# MDR1206AFI register map
Vendor: Milandr; File version: 2.0
CPU: BM-310S0, little endian
Registers are 32-bit, read-write, reset 0x0 unless marked. A register's access mark holds for its fields unless they carry their own. Offsets are from the block's base; [hi:lo] are bit positions; {n}, {i} and the like mark numbered series; 'fields as' and 'values as' point back to an identical list.

## DMA — DMA Controller
Base 0x50028000
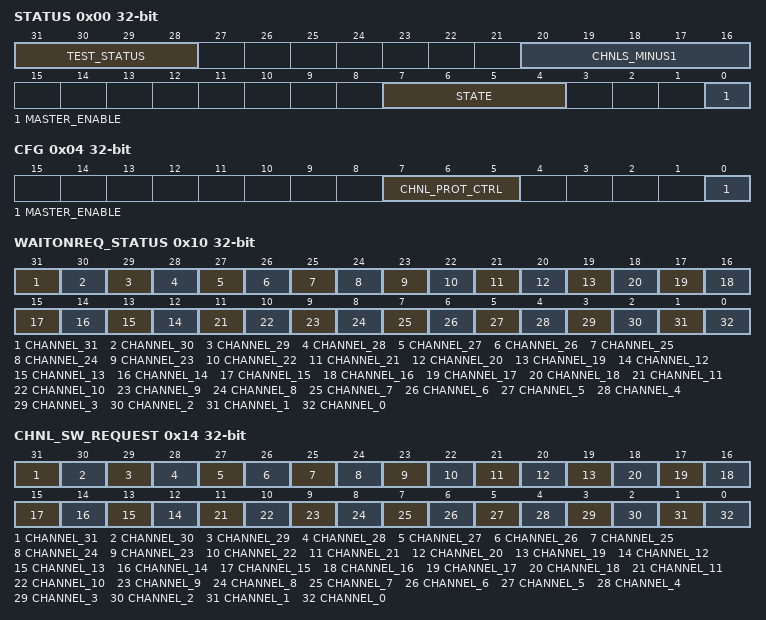
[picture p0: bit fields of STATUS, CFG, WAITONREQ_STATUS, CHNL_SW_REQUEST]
0x00 STATUS ro
  [31:28] TEST_STATUS — Defines if there is an in-built testing system
    0=NO_TESTING_SYSTEM; 1=TESTING_SYSTEM
  [20:16] CHNLS_MINUS1 — The number of available DMA channels minus one
  [7:4] STATE — A current state of the DMA Controller
    0=idle; 1=reading channel control data; 2=reading source data end pointer; 3=reading destination data end pointer; 4=reading source data; 5=writing destination data; 6=waiting for DMA request to clear; 7=writing channel controller data; 8=stalled; 9=done; 10=peripheral scatter-gather transition; 11=undefined
  [0] MASTER_ENABLE — Enables the status of the controller
    0=The controller is disabled; 1=The controller is enabled
0x04 CFG — DMA Configuration Register
  [7:5] CHNL_PROT_CTRL wo — Sets the AHB-Lite protection by controlling the HPROT[3:1] signal levels
  [0] MASTER_ENABLE wo — Enables the DMA controller
    0=Disables DMA; 1=Enables DMA
0x08 CTRL_BASE_PTR — Channel control data base pointer
0x0C ALT_CTRL_BASE_PTR ro — Channel alternate control data base pointer
0x10 WAITONREQ_STATUS ro — Channel wait on request status
  [31] CHANNEL_31
  [30] CHANNEL_30 — CHANNEL_30: SAR ADC
  [29] CHANNEL_29 — CHANNEL_26
  [28] CHANNEL_28
  [27] CHANNEL_27
  [26] CHANNEL_26
  [25] CHANNEL_25 — CHANNEL_25: UART4 RX
  [24] CHANNEL_24 — CHANNEL_24: UART4 TX
  [23] CHANNEL_23 — CHANNEL_23: TIMER4
  [22] CHANNEL_22 — CHANNEL_22: SSP3 RX
  [21] CHANNEL_21 — CHANNEL_21: SSP3 TX
  [20] CHANNEL_20 — CHANNEL_20: SSP2 RX
  [19] CHANNEL_19 — CHANNEL_19: SSP2 TX
  [n] CHANNEL_{n} (n=12..18) — CHANNEL_{n}: ADCUI{n-11}
  [11] CHANNEL_11 — CHANNEL_11: TIMER2
  [10] CHANNEL_10 — CHANNEL_10: TIMER1
  [9] CHANNEL_9 — CHANNEL_9: TIMER3
  [8] CHANNEL_8 — CHANNEL_8: UART3 RX
  [7] CHANNEL_7 — CHANNEL_7: UART3 TX
  [6] CHANNEL_6 — CHANNEL_6: CRC
  [5] CHANNEL_5 — CHANNEL_5: SSP1 RX
  [4] CHANNEL_4 — CHANNEL_4: SSP1 TX
  [3] CHANNEL_3 — CHANNEL_3: UART2 RX
  [2] CHANNEL_2 — CHANNEL_2: UART2 TX
  [1] CHANNEL_1 — CHANNEL_1: UART1 RX
  [0] CHANNEL_0 — CHANNEL_0: UART1 TX
0x14 CHNL_SW_REQUEST wo — Channel software request. Set the appropriate bit to generate a software DMA request on the corresponding DMA channel
  fields as WAITONREQ_STATUS
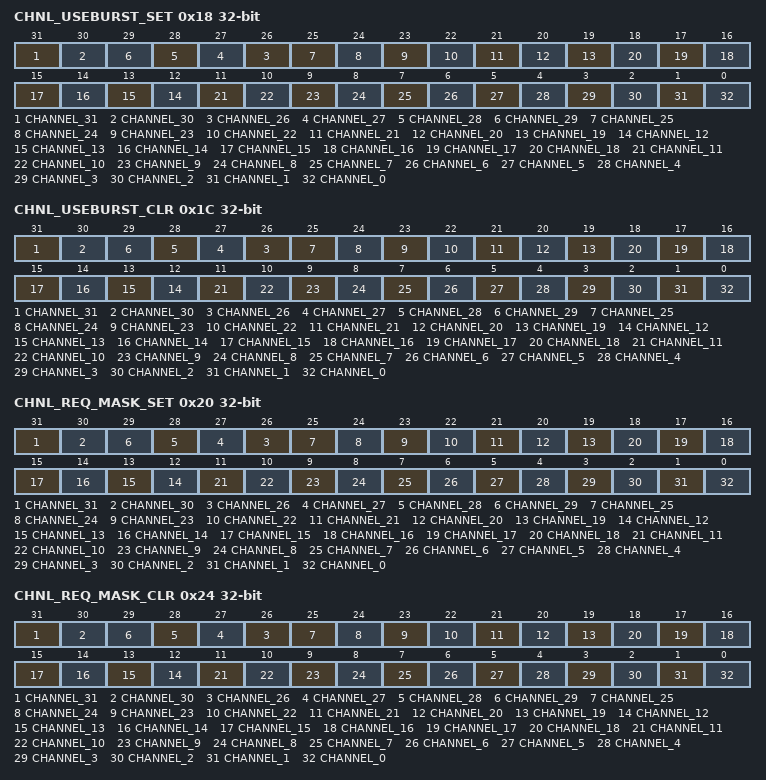
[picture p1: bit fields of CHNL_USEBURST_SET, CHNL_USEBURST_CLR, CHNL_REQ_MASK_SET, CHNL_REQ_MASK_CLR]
0x18 CHNL_USEBURST_SET — Channel useburst set. Returns the useburst status, or disables dma_sreq[C] from generating DMA requests.
  [31] CHANNEL_31
  [30] CHANNEL_30 — CHANNEL_30: SAR ADC
  [n] CHANNEL_{n} (n=26..29)
  [25] CHANNEL_25 — CHANNEL_25: UART4 RX
  [24] CHANNEL_24 — CHANNEL_24: UART4 TX
  [23] CHANNEL_23 — CHANNEL_23: TIMER4
  [22] CHANNEL_22 — CHANNEL_22: SSP3 RX
  [21] CHANNEL_21 — CHANNEL_21: SSP3 TX
  [20] CHANNEL_20 — CHANNEL_20: SSP2 RX
  [19] CHANNEL_19 — CHANNEL_19: SSP2 TX
  [n] CHANNEL_{n} (n=12..18) — CHANNEL_{n}: ADCUI{n-11}
  [11] CHANNEL_11 — CHANNEL_11: TIMER2
  [10] CHANNEL_10 — CHANNEL_10: TIMER1
  [9] CHANNEL_9 — CHANNEL_9: TIMER3
  [8] CHANNEL_8 — CHANNEL_8: UART3 RX
  [7] CHANNEL_7 — CHANNEL_7: UART3 TX
  [6] CHANNEL_6 — CHANNEL_5: CRC
  [5] CHANNEL_5 — CHANNEL_5: SSP1 RX
  [4] CHANNEL_4 — CHANNEL_4: SSP1 TX
  [3] CHANNEL_3 — CHANNEL_3: UART2 RX
  [2] CHANNEL_2 — CHANNEL_2: UART2 TX
  [1] CHANNEL_1 — CHANNEL_1: UART1 RX
  [0] CHANNEL_0 — CHANNEL_0: UART1 TX
0x1C CHNL_USEBURST_CLR wo — Channel useburst clear. Set the appropriate bit to enable dma_sreq[] to generate requests
  fields as CHNL_USEBURST_SET
0x20 CHNL_REQ_MASK_SET — Channel request mask set. Returns the request mask status of dma_req[] and dma_sreq[], or disables the corresponding channel from generating DMA requests
  fields as CHNL_USEBURST_SET
0x24 CHNL_REQ_MASK_CLR wo — Channel request mask clear. Set the appropriate bit to enable DMA requests for the channel corresponding to dma_req[] and dma_sreq[].
  fields as CHNL_USEBURST_SET
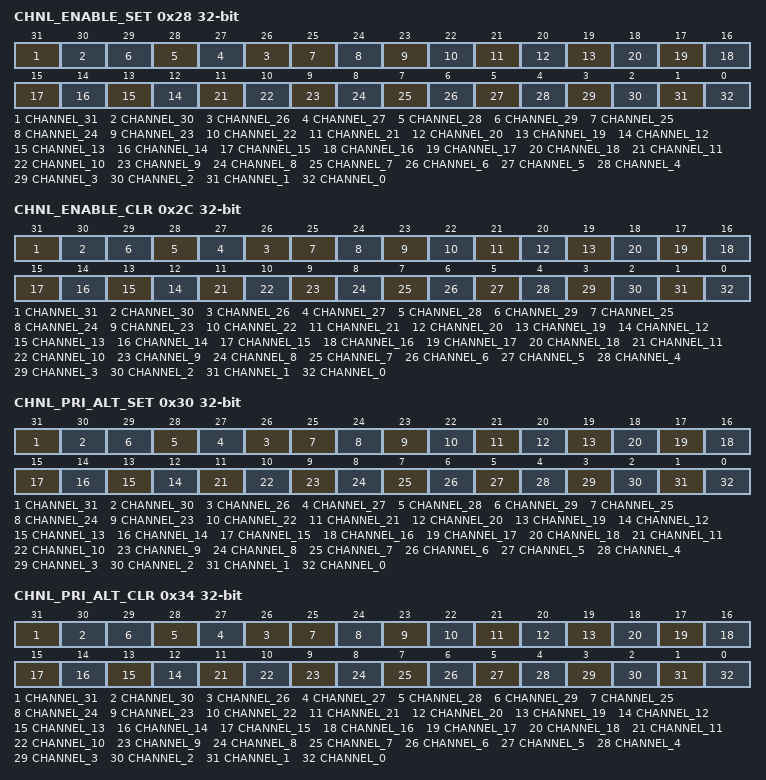
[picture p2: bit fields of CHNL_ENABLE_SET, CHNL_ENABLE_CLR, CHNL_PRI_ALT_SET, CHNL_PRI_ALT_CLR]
0x28 CHNL_ENABLE_SET — Channel enable set. Returns the enable status of the channels, or enables the corresponding channels
  fields as CHNL_USEBURST_SET
0x2C CHNL_ENABLE_CLR wo — Sets the appropriate bit to disable the corresponding DMA channel
  fields as CHNL_USEBURST_SET
0x30 CHNL_PRI_ALT_SET — Channel primary-alternate set register enables you to configure a DMA channel to use the alternate data structure or returns the channel control data structure status.
  fields as CHNL_USEBURST_SET
0x34 CHNL_PRI_ALT_CLR wo — Channel primary-alternate clear register enables you to configure a DMA channel to use the primary data structure
  fields as CHNL_USEBURST_SET
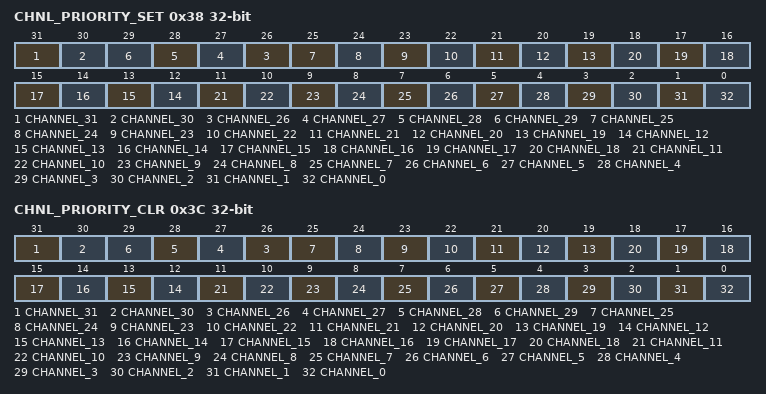
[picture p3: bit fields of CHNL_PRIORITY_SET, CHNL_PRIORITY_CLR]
0x38 CHNL_PRIORITY_SET — Channel priority set enables you to configure a DMA channel to use the high priority level. Reading the register returns the status of the channel priority mask.
  fields as CHNL_USEBURST_SET
0x3C CHNL_PRIORITY_CLR wo — Channel priority clear register enables you to configure a DMA channel to use the default priority level
  fields as CHNL_USEBURST_SET
0x4C ERR_CLR — Error clear register enables you to set dma_err LOW
  [0] ERR_CLR — Returns the status of dma_err, or sets the signal LOW
